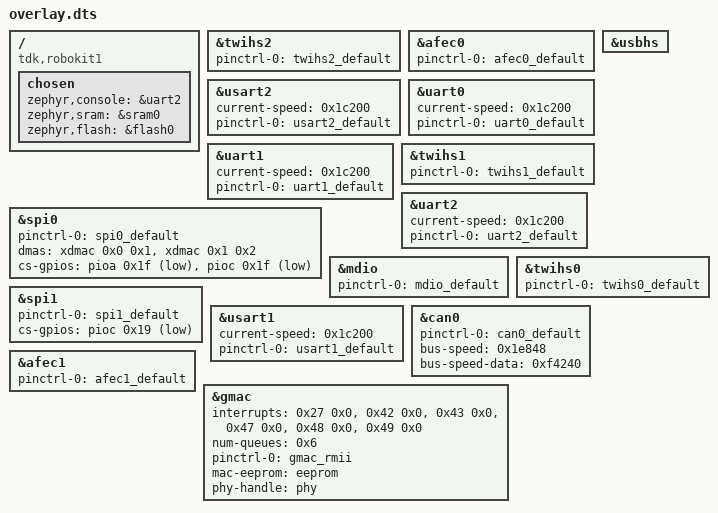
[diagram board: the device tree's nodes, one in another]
/ {
	compatible = "tdk,robokit1", "atmel,same70q21", "atmel,same70";
	chosen {
		zephyr,console = &uart2;
		zephyr,sram = &sram0;
		zephyr,flash = &flash0;
	};
};
&twihs2{
	status = "okay";
	pinctrl-0 = < &twihs2_default >;
	pinctrl-names = "default";
};
&afec0{
	status = "okay";
	pinctrl-0 = < &afec0_default >;
	pinctrl-names = "default";
};
&usart2{
	status = "okay";
	current-speed = < 0x1c200 >;
	pinctrl-0 = < &usart2_default >;
	pinctrl-names = "default";
};
&uart0{
	status = "okay";
	current-speed = < 0x1c200 >;
	pinctrl-0 = < &uart0_default >;
	pinctrl-names = "default";
};
&uart1{
	status = "okay";
	current-speed = < 0x1c200 >;
	pinctrl-0 = < &uart1_default >;
	pinctrl-names = "default";
};
&twihs1{
	status = "okay";
	pinctrl-0 = < &twihs1_default >;
	pinctrl-names = "default";
};
&spi0{
	status = "okay";
	pinctrl-0 = < &spi0_default >;
	pinctrl-names = "default";
	dmas = < &xdmac 0x0 0x1 >, < &xdmac 0x1 0x2 >;
	dma-names = "tx", "rx";
	cs-gpios = < &pioa 0x1f 0x1 >, < &pioc 0x1f 0x1 >;
};
&usbhs{
	status = "okay";
};
&uart2{
	status = "okay";
	current-speed = < 0x1c200 >;
	pinctrl-0 = < &uart2_default >;
	pinctrl-names = "default";
};
&mdio{
	status = "okay";
	pinctrl-0 = < &mdio_default >;
	pinctrl-names = "default";
};
&twihs0{
	status = "okay";
	pinctrl-0 = < &twihs0_default >;
	pinctrl-names = "default";
};
&spi1{
	status = "okay";
	pinctrl-0 = < &spi1_default >;
	pinctrl-names = "default";
	cs-gpios = < &pioc 0x19 0x1 >;
};
&usart1{
	status = "okay";
	current-speed = < 0x1c200 >;
	pinctrl-0 = < &usart1_default >;
	pinctrl-names = "default";
};
&can0{
	status = "okay";
	pinctrl-0 = < &can0_default >;
	pinctrl-names = "default";
	bus-speed = < 0x1e848 >;
	bus-speed-data = < 0xf4240 >;
};
&afec1{
	status = "okay";
	pinctrl-0 = < &afec1_default >;
	pinctrl-names = "default";
};
&gmac{
	interrupts = < 0x27 0x0 >, < 0x42 0x0 >, < 0x43 0x0 >, < 0x47 0x0 >, < 0x48 0x0 >, < 0x49 0x0 >;
	interrupt-names = "gmac", "q1", "q2", "q3", "q4", "q5";
	num-queues = < 0x6 >;
	status = "okay";
	pinctrl-0 = < &gmac_rmii >;
	pinctrl-names = "default";
	mac-eeprom = < &eeprom >;
	phy-handle = < &phy >;
};
